# CH32V30xxx register map
Vendor: WCH Ltd.; File version: 1.0
Registers are 32-bit, read-write, reset 0x0 unless marked. A register's access mark holds for its fields unless they carry their own. Offsets are from the block's base; [hi:lo] are bit positions; {n}, {i} and the like mark numbered series.

## SysTick — System Tick Timer
Base 0xE000F000
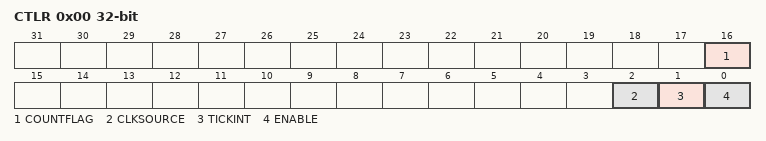
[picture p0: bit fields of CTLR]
0x00 CTLR access per field — Control and Status Register
  [16] COUNTFLAG ro — Indicates counter reached zero
  [2] CLKSOURCE rw — Clock Source
  [1] TICKINT rw — Enable SysTick Interrupt
  [0] ENABLE rw — Enable SysTick Timer
0x04 LOAD access not given — SysTick Reload Value Register
0x08 VAL access not given — SysTick Current Value Register
0x0C CALIB ro — SysTick Calibration Value Register
  [23:0] TICK — Number of ticks per second

## RNG — Random number generator
Base 0x40023C00
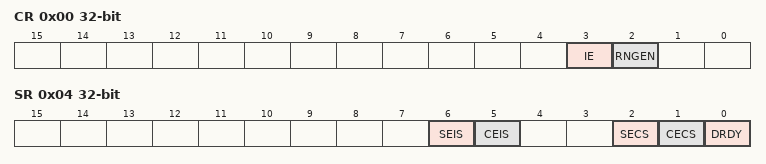
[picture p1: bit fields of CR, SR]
0x00 CR — control register
  [3] IE — Interrupt enable
  [2] RNGEN — Random number generator enable
0x04 SR access per field — status register
  [6] SEIS rw — Seed error interrupt status
  [5] CEIS rw — Clock error interrupt status
  [2] SECS ro — Seed error current status
  [1] CECS ro — Clock error current status
  [0] DRDY ro — Data ready
0x08 DR ro — data register
  [31:0] RNDATA — Random data

## USB — Universal serial bus full-speed device interface
Base 0x40005C00
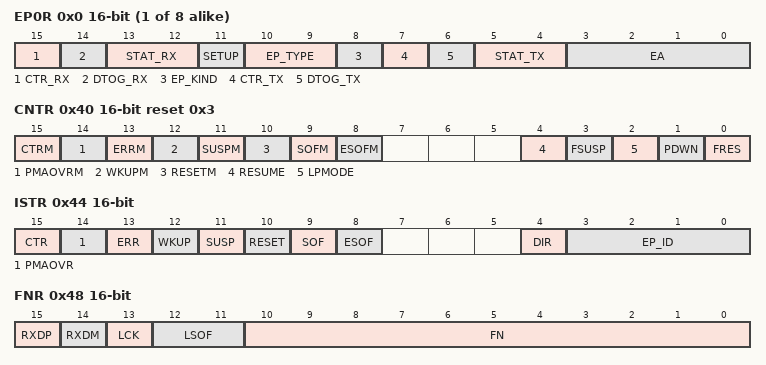
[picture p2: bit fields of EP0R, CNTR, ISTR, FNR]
{0x0+4i} EP{i}R 16-bit (i=0..7) — endpoint {i} register
  [15] CTR_RX — Correct transfer for reception
  [14] DTOG_RX — Data Toggle, for reception transfers
  [13:12] STAT_RX — Status bits, for reception transfers
  [11] SETUP — Setup transaction completed
  [10:9] EP_TYPE — Endpoint type
  [8] EP_KIND — Endpoint kind
  [7] CTR_TX — Correct Transfer for transmission
  [6] DTOG_TX — Data Toggle, for transmission transfers
  [5:4] STAT_TX — Status bits, for transmission transfers
  [3:0] EA — Endpoint address
0x40 CNTR 16-bit reset 0x3 — control register
  [15] CTRM — Correct transfer interrupt mask
  [14] PMAOVRM — Packet memory area over / underrun interrupt mask
  [13] ERRM — Error interrupt mask
  [12] WKUPM — Wakeup interrupt mask
  [11] SUSPM — Suspend mode interrupt mask
  [10] RESETM — USB reset interrupt mask
  [9] SOFM — Start of frame interrupt mask
  [8] ESOFM — Expected start of frame interrupt mask
  [4] RESUME — Resume request
  [3] FSUSP — Force suspend
  [2] LPMODE — Low-power mode
  [1] PDWN — Power down
  [0] FRES — Force USB Reset
0x44 ISTR 16-bit — interrupt status register
  [15] CTR — Correct transfer
  [14] PMAOVR — Packet memory area over / underrun
  [13] ERR — Error
  [12] WKUP — Wakeup
  [11] SUSP — Suspend mode request
  [10] RESET — reset request
  [9] SOF — start of frame
  [8] ESOF — Expected start frame
  [4] DIR — Direction of transaction
  [3:0] EP_ID — Endpoint Identifier
0x48 FNR 16-bit ro — frame number register
  [15] RXDP — Receive data + line status
  [14] RXDM — Receive data - line status
  [13] LCK — Locked
  [12:11] LSOF — Lost SOF
  [10:0] FN — Frame number
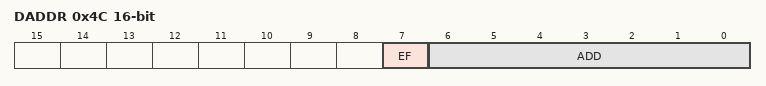
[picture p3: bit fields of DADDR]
0x4C DADDR 16-bit — device address
  [7] EF — Enable function
  [6:0] ADD — Device address
0x50 BTABLE — Buffer table address
  [15:3] BTABLE — Buffer table

## ETHERNET_MMC — Ethernet: MAC management counters
Base 0x40028100
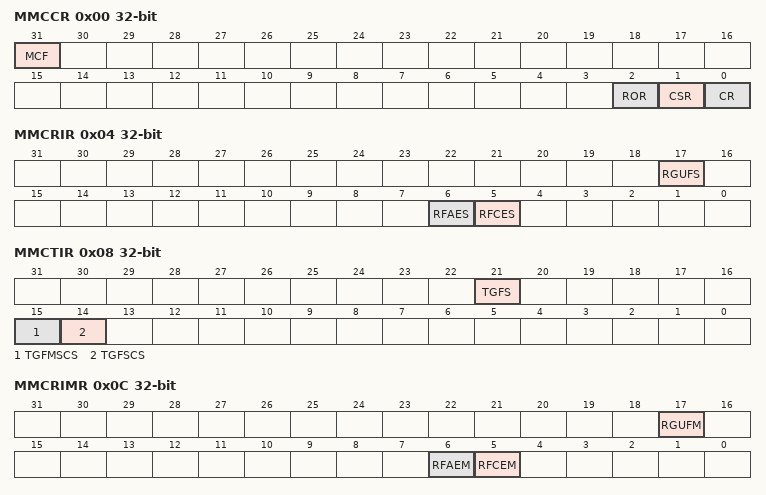
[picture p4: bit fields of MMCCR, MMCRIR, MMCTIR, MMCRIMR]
0x00 MMCCR — Ethernet MMC control register (ETH_MMCCR)
  [31] MCF — MMC counter freeze
  [2] ROR — Reset on read
  [1] CSR — Counter stop rollover
  [0] CR — Counter reset
0x04 MMCRIR — Ethernet MMC receive interrupt register (ETH_MMCRIR)
  [17] RGUFS — Received Good Unicast Frames Status
  [6] RFAES — Received frames alignment error status
  [5] RFCES — Received frames CRC error status
0x08 MMCTIR — Ethernet MMC transmit interrupt register (ETH_MMCTIR)
  [21] TGFS — Transmitted good frames status
  [15] TGFMSCS — Transmitted good frames more single collision status
  [14] TGFSCS — Transmitted good frames single collision status
0x0C MMCRIMR — Ethernet MMC receive interrupt mask register (ETH_MMCRIMR)
  [17] RGUFM — Received good unicast frames mask
  [6] RFAEM — Received frames alignment error mask
  [5] RFCEM — Received frame CRC error mask
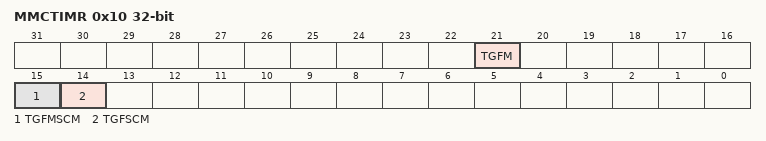
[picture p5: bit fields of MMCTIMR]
0x10 MMCTIMR — Ethernet MMC transmit interrupt mask register (ETH_MMCTIMR)
  [21] TGFM — Transmitted good frames mask
  [15] TGFMSCM — Transmitted good frames more single collision mask
  [14] TGFSCM — Transmitted good frames single collision mask
0x4C MMCTGFSCCR ro — Ethernet MMC transmitted good frames after a single collision counter
  [31:0] TGFSCC — Transmitted good frames after a single collision counter
0x50 MMCTGFMSCCR ro — Ethernet MMC transmitted good frames after more than a single collision
  [31:0] TGFMSCC — Transmitted good frames after more than a single collision counter
0x68 MMCTGFCR ro — Ethernet MMC transmitted good frames counter register
  [31:0] TGFC — Transmitted good frames counter
0x94 MMCRFCECR ro — Ethernet MMC received frames with CRC error counter register
  [31:0] RFCFC — Received frames with CRC error counter
0x98 MMCRFAECR ro — Ethernet MMC received frames with alignment error counter register
  [31:0] RFAEC — Received frames with alignment error counter
0xC4 MMCRGUFCR ro — MMC received good unicast frames counter register
  [31:0] RGUFC — Received good unicast frames counter
